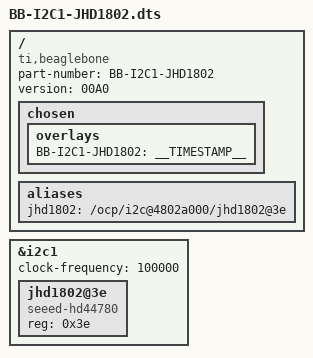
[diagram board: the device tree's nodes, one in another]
/*
 * Copyright (C) 2019 Seeed Studio
 * Peter Yang <turmary@126.com>
 *
 * MIT License
 *
 */
/dts-v1/;
/plugin/;

/ {
        compatible = "ti,beaglebone", "ti,beaglebone-black", "ti,beaglebone-green";

	/* identification */
	part-number = "BB-I2C1-JHD1802";
	version = "00A0";        
	fragment@0 {
		target-path="/";
		__overlay__ {
			chosen {
				overlays {
					BB-I2C1-JHD1802 = __TIMESTAMP__;
				};
			};

			aliases {
				/* SLOT I2C1 */
				jhd1802 = "/ocp/i2c@4802a000/jhd1802@3e";
				/* SLOT I2C2 */
				/*
				jhd1802 = "/ocp/i2c@4819c000/jhd1802@3e";
				*/
			};
		};
	};

	fragment@1 {
		/* SLOT I2C1 */
		target = <&i2c1>;
		/* SLOT I2C2 */
		/*
		target = <&i2c2>;
		*/
		__overlay__ {
			status = "okay";

			/* this is the configuration part */
			clock-frequency = <100000>;

			#address-cells = <1>;
			#size-cells = <0>;

			jhd1802@3e {
				compatible = "seeed-hd44780";
				reg = <0x3e>;
				status = "okay";
			};
		};
	};
};

